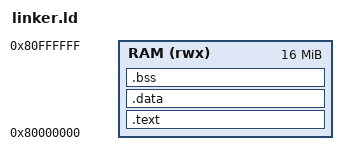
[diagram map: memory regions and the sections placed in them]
OUTPUT_ARCH(riscv)
ENTRY(_start)

MEMORY {
    RAM (rwx) : ORIGIN = 0x80000000, LENGTH = 16M
}

_estack = ORIGIN(RAM) + LENGTH(RAM);

SECTIONS {
    .text : {
        KEEP(*(.text.init))
        *(.text*)
        *(.rodata*)
        . = ALIGN(8);
    } > RAM

    _sidata = LOADADDR(.data);

    .data : ALIGN(8) {
        _sdata = .;
        *(.data*)
        . = ALIGN(8);
        _edata = .;
    } > RAM AT > RAM

    .bss : ALIGN(8) {
        _sbss = .;
        *(.bss*)
        *(COMMON)
        . = ALIGN(8);
        _ebss = .;
    } > RAM
}
